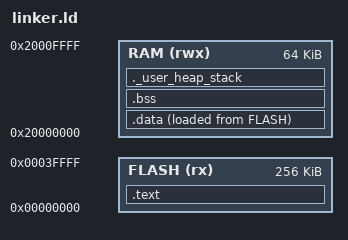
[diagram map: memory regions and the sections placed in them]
/* linker.ld — LM3S6965 (QEMU target: -M lm3s6965evb) */

MEMORY
{
    FLASH (rx)  : ORIGIN = 0x00000000, LENGTH = 256K
    RAM   (rwx) : ORIGIN = 0x20000000, LENGTH = 64K  /* renamed SRAM -> RAM */
}

PROVIDE(_estack = ORIGIN(RAM) + LENGTH(RAM));

ENTRY(Reset_Handler)

SECTIONS
{
    .text :
    {
        KEEP(*(.isr_vector))
        *(.text)
        *(.text*)
        *(.rodata)
        *(.rodata*)
        KEEP(*(.init))
        KEEP(*(.fini))
        . = ALIGN(4);
        _etext = .;
    } > FLASH

    /* Load address of .data — used by startup to copy Flash -> RAM */
    _sidata = LOADADDR(.data);

    .data :
    {
        . = ALIGN(4);
        _sdata = .;
        *(.data)
        *(.data*)
        . = ALIGN(4);
        _edata = .;
    } > RAM AT > FLASH

    .bss :
    {
        . = ALIGN(4);
        _sbss = .;
        *(.bss)
        *(.bss*)
        *(COMMON)
        . = ALIGN(4);
        _ebss = .;
    } > RAM

    ._user_heap_stack :
    {
        . = ALIGN(8);
        PROVIDE(end = .);
        . = . + 0x400;
        . = ALIGN(8);
    } > RAM
}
